# STM32L100RCT6 register map
File version: 1.0
Registers are 32-bit, access not given, reset 0x0 unless marked. A register's access mark holds for its fields unless they carry their own. Offsets are from the block's base; [hi:lo] are bit positions; {n}, {i} and the like mark numbered series; 'fields as' and 'values as' point back to an identical list.

## COMP
Base 0x40007C00
Same registers: COMP1 0x40007C00, COMP12_COMMON 0x40007C00, COMP2 0x40007C01
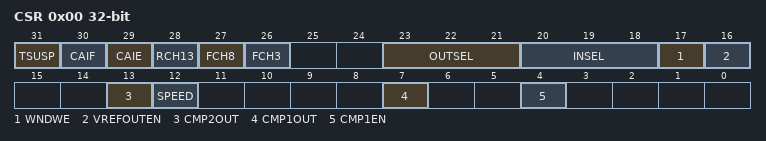
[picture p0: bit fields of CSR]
0x00 CSR
  [31] TSUSP, [30] CAIF, [29] CAIE, [28] RCH13, [27] FCH8, [26] FCH3, [23:21] OUTSEL, [20:18] INSEL, [17] WNDWE, [16] VREFOUTEN, [13] CMP2OUT, [12] SPEED, [7] CMP1OUT, [4] CMP1EN

## RI
Base 0x40007C04
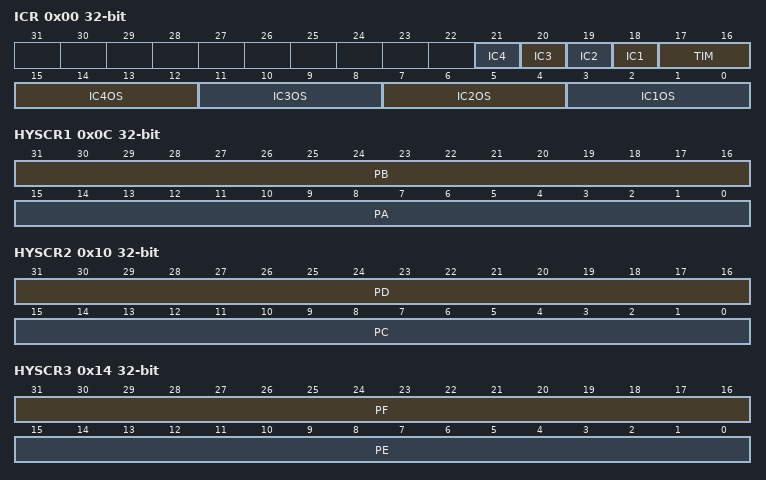
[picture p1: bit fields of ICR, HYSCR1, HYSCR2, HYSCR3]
0x00 ICR
  [n+17] IC{n} (n=1..4), [17:16] TIM, [4n-1:4n-4] IC{n}OS (n=1..4)
0x04 ASCR1
  [31] SCM, [26] VCOMP, [30:0] CH
0x08 ASCR2
  [16] CH0b, [28:4] GR6
0x0C HYSCR1
  [31:16] PB, [15:0] PA
0x10 HYSCR2
  [31:16] PD, [15:0] PC
0x14 HYSCR3
  [31:16] PF, [15:0] PE
0x18 HYSCR4
  [15:0] PG
0x1C ASMR1
  [15:0] PA
0x20 CMR1
  [15:0] PA
0x24 CICR1
  [15:0] PA
0x28 ASMR2
  [15:0] PB
0x2C CMR2
  [15:0] PB
0x30 CICR2
  [15:0] PB
0x34 ASMR3
  [15:0] PC
0x38 CMR3
  [15:0] PC
0x3C CICR3
  [15:0] PC
0x40 ASMR4
  [15:0] PF
0x44 CMR4
  [15:0] PF
0x48 CICR4
  [15:0] PF
0x4C ASMR5
  [15:0] PG
0x50 CMR5
  [15:0] PG
0x54 CICR5
  [15:0] PG

## SYSCFG
Base 0x40010000
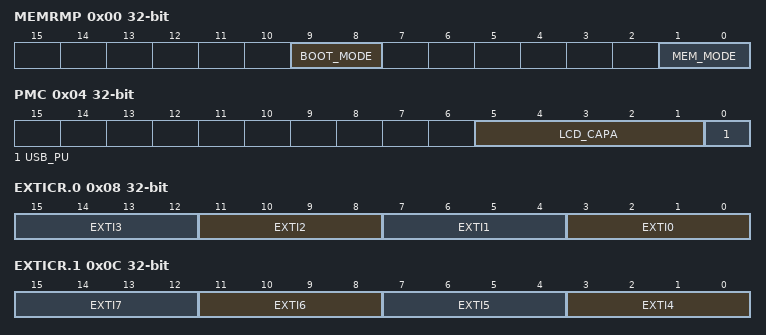
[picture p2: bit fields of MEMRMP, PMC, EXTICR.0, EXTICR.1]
0x00 MEMRMP
  [9:8] BOOT_MODE, [1:0] MEM_MODE
0x04 PMC
  [5:1] LCD_CAPA, [0] USB_PU
0x08 EXTICR.0
  [4n+3:4n] EXTI{n} (n=0..3)
0x0C EXTICR.1
  [4n-13:4n-16] EXTI{n} (n=4..7)
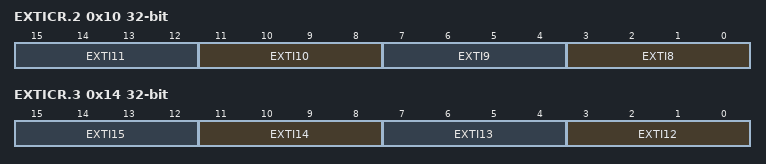
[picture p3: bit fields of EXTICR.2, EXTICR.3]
0x10 EXTICR.2
  [4n-29:4n-32] EXTI{n} (n=8..11)
0x14 EXTICR.3
  [4n-45:4n-48] EXTI{n} (n=12..15)

## EXTI
Base 0x40010400
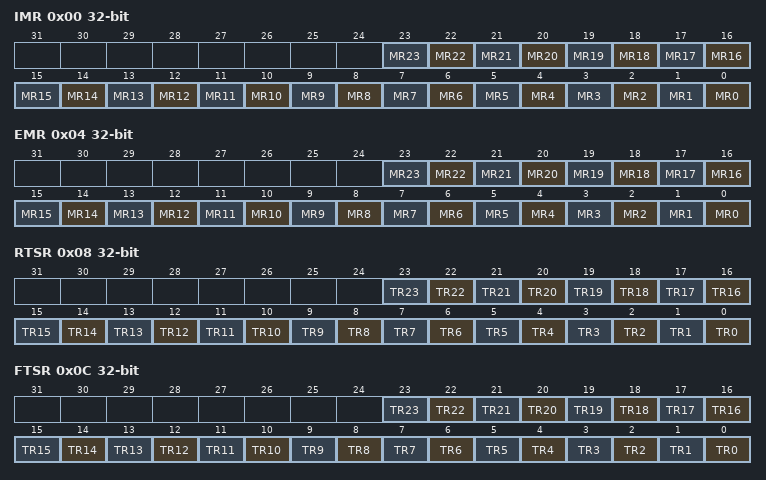
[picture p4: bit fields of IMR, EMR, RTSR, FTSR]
0x00 IMR
  [n] MR{n} (n=0..23)
0x04 EMR
  [n] MR{n} (n=0..23)
0x08 RTSR
  [n] TR{n} (n=0..23)
0x0C FTSR
  [n] TR{n} (n=0..23)
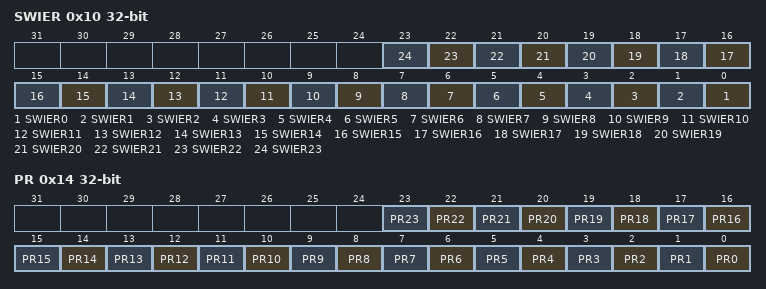
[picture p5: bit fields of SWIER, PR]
0x10 SWIER
  [n] SWIER{n} (n=0..23)
0x14 PR
  [n] PR{n} (n=0..23)

## ADC1
Base 0x40012400
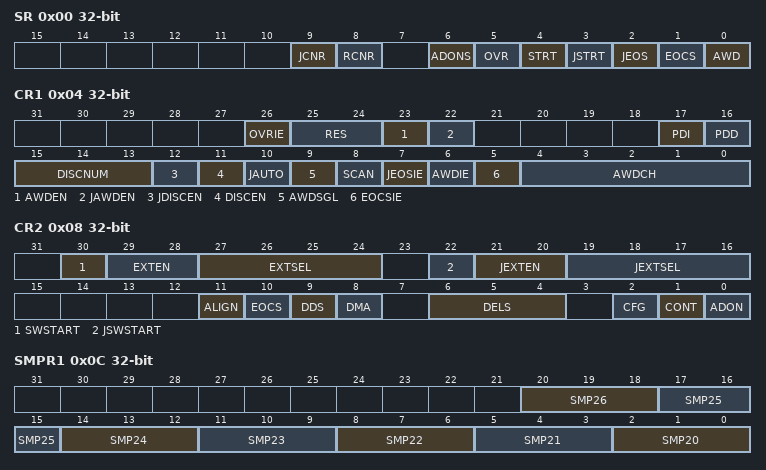
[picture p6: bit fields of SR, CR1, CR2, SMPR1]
0x00 SR
  [9] JCNR, [8] RCNR, [6] ADONS, [5] OVR, [4] STRT, [3] JSTRT, [2] JEOS, [1] EOCS, [0] AWD
0x04 CR1
  [26] OVRIE, [25:24] RES, [23] AWDEN, [22] JAWDEN, [17] PDI, [16] PDD, [15:13] DISCNUM, [12] JDISCEN, [11] DISCEN, [10] JAUTO, [9] AWDSGL, [8] SCAN, [7] JEOSIE, [6] AWDIE, [5] EOCSIE, [4:0] AWDCH
0x08 CR2
  [30] SWSTART, [29:28] EXTEN, [27:24] EXTSEL, [22] JSWSTART, [21:20] JEXTEN, [19:16] JEXTSEL, [11] ALIGN, [10] EOCS, [9] DDS, [8] DMA, [6:4] DELS, [2] CFG, [1] CONT, [0] ADON
0x0C SMPR1
  [3n-58:3n-60] SMP{n} (n=20..26)
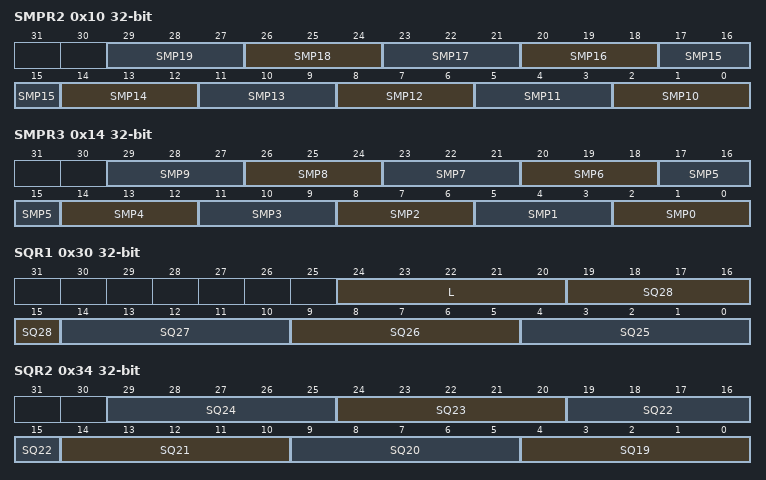
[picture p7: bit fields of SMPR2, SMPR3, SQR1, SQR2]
0x10 SMPR2
  [3n-28:3n-30] SMP{n} (n=10..19)
0x14 SMPR3
  [3n+2:3n] SMP{n} (n=0..9)
{0x14+4i} JOFR{i} (i=1..4)
  [11:0] JOFFSET{i}
0x28 HTR
  [11:0] HT
0x2C LTR
  [11:0] LT
0x30 SQR1
  [24:20] L, [5n-121:5n-125] SQ{n} (n=25..28)
0x34 SQR2
  [5n-91:5n-95] SQ{n} (n=19..24)
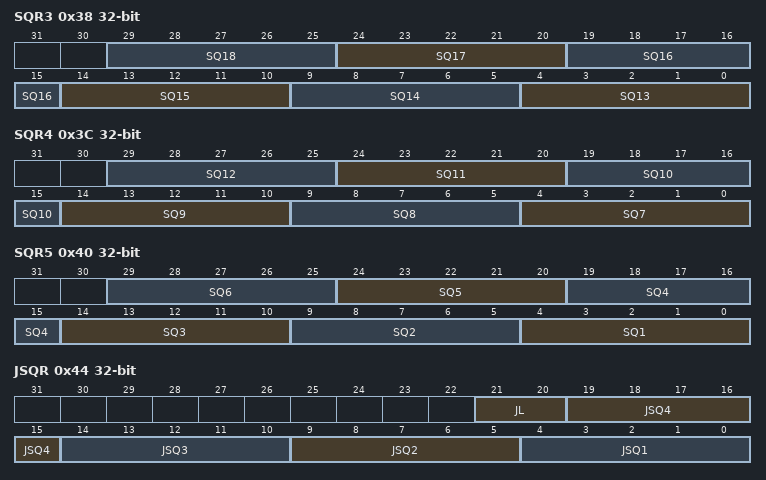
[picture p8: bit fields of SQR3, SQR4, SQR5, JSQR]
0x38 SQR3
  [5n-61:5n-65] SQ{n} (n=13..18)
0x3C SQR4
  [5n-31:5n-35] SQ{n} (n=7..12)
0x40 SQR5
  [5n-1:5n-5] SQ{n} (n=1..6)
0x44 JSQR
  [21:20] JL, [5n-1:5n-5] JSQ{n} (n=1..4)
{0x44+4i} JDR{i} (i=1..4)
  [15:0] JDATA
0x58 DR
  [15:0] DATA
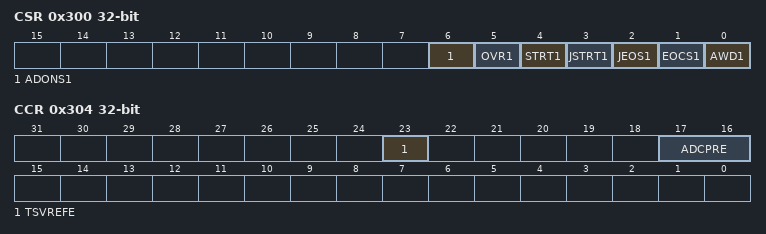
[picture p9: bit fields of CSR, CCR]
0x300 CSR
  [6] ADONS1, [5] OVR1, [4] STRT1, [3] JSTRT1, [2] JEOS1, [1] EOCS1, [0] AWD1
0x304 CCR
  [23] TSVREFE, [17:16] ADCPRE

## GPIOA
Base 0x40020000
Same registers: GPIOB 0x40020400, GPIOC 0x40020800, GPIOD 0x40020C00, GPIOH 0x40021400
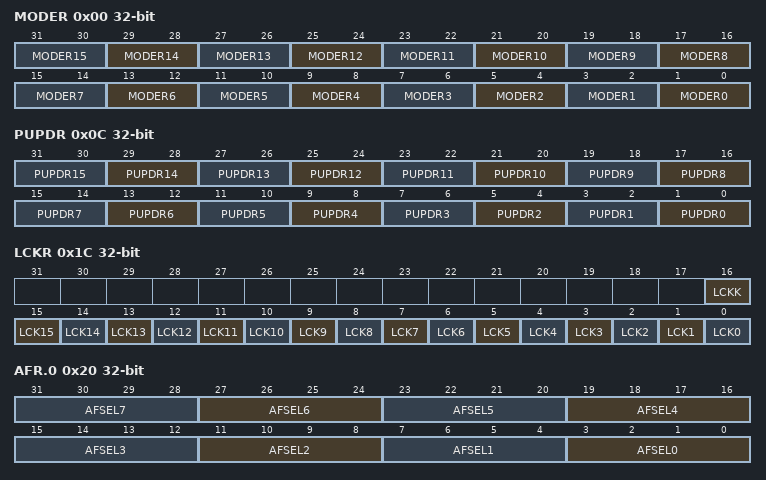
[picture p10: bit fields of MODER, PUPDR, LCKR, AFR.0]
0x00 MODER
  [2n+1:2n] MODER{n} (n=0..15)
0x04 OTYPER
0x08 OSPEEDR
0x0C PUPDR
  [2n+1:2n] PUPDR{n} (n=0..15)
0x10 IDR
0x14 ODR
0x18 BSRR
0x1C LCKR
  [16] LCKK, [n] LCK{n} (n=0..15)
0x20 AFR.0
  [4n+3:4n] AFSEL{n} (n=0..7)
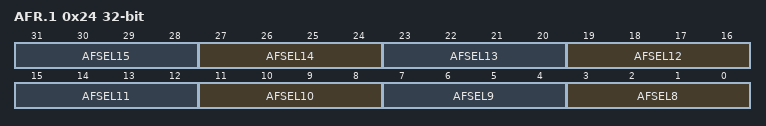
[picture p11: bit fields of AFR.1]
0x24 AFR.1
  [4n-29:4n-32] AFSEL{n} (n=8..15)

## CRC
Base 0x40023000
0x00 DR
0x04 IDR 8-bit
0x08 CR
  [0] RESET

## RCC
Base 0x40023800
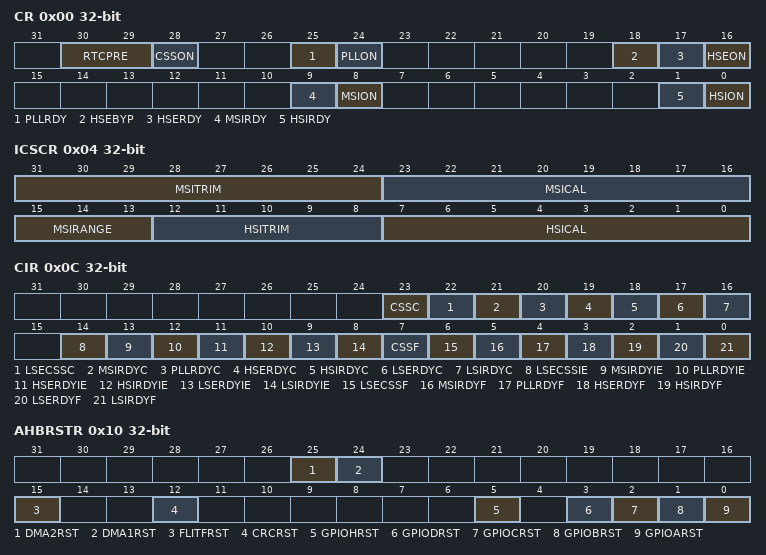
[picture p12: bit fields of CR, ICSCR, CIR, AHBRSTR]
0x00 CR
  [30:29] RTCPRE, [28] CSSON, [25] PLLRDY, [24] PLLON, [18] HSEBYP, [17] HSERDY, [16] HSEON, [9] MSIRDY, [8] MSION, [1] HSIRDY, [0] HSION
0x04 ICSCR
  [31:24] MSITRIM, [23:16] MSICAL, [15:13] MSIRANGE, [12:8] HSITRIM, [7:0] HSICAL
0x08 CFGR
  [30:28] MCOPRE, [26] MCOSEL_HSE, [26:25] MCOSEL_LSI, [24] MCOSEL_SYSCLK, [23] PLLDIV3, [23:22] PLLDIV4, [21:18] PLLMUL, [16] PLLSRC, [13:11] PPRE2, [10:8] PPRE1, [7:4] HPRE, [3:2] SWS, [1:0] SW
0x0C CIR
  [23] CSSC, [22] LSECSSC, [21] MSIRDYC, [20] PLLRDYC, [19] HSERDYC, [18] HSIRDYC, [17] LSERDYC, [16] LSIRDYC, [14] LSECSSIE, [13] MSIRDYIE, [12] PLLRDYIE, [11] HSERDYIE, [10] HSIRDYIE, [9] LSERDYIE, [8] LSIRDYIE, [7] CSSF, [6] LSECSSF, [5] MSIRDYF, [4] PLLRDYF, [3] HSERDYF, [2] HSIRDYF, [1] LSERDYF, [0] LSIRDYF
0x10 AHBRSTR
  [25] DMA2RST, [24] DMA1RST, [15] FLITFRST, [12] CRCRST, [5] GPIOHRST, [3] GPIODRST, [2] GPIOCRST, [1] GPIOBRST, [0] GPIOARST
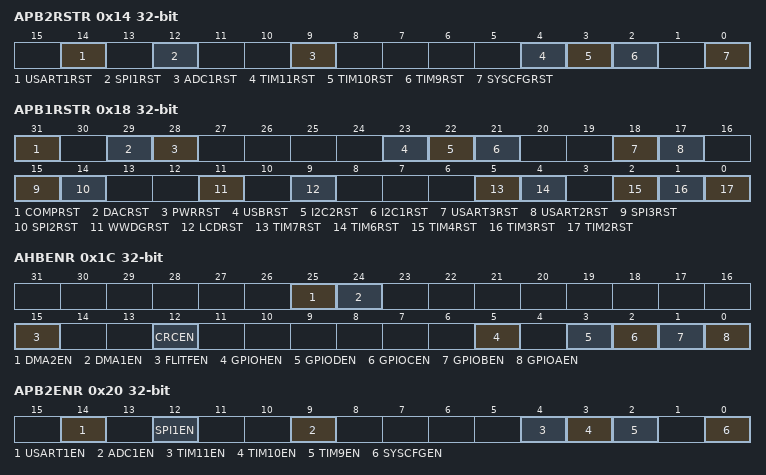
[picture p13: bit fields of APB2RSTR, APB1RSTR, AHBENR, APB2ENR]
0x14 APB2RSTR
  [14] USART1RST, [12] SPI1RST, [9] ADC1RST, [4] TIM11RST, [3] TIM10RST, [2] TIM9RST, [0] SYSCFGRST
0x18 APB1RSTR
  [31] COMPRST, [29] DACRST, [28] PWRRST, [23] USBRST, [22] I2C2RST, [21] I2C1RST, [18] USART3RST, [17] USART2RST, [15] SPI3RST, [14] SPI2RST, [11] WWDGRST, [9] LCDRST, [5] TIM7RST, [4] TIM6RST, [2] TIM4RST, [1] TIM3RST, [0] TIM2RST
0x1C AHBENR
  [25] DMA2EN, [24] DMA1EN, [15] FLITFEN, [12] CRCEN, [5] GPIOHEN, [3] GPIODEN, [2] GPIOCEN, [1] GPIOBEN, [0] GPIOAEN
0x20 APB2ENR
  [14] USART1EN, [12] SPI1EN, [9] ADC1EN, [4] TIM11EN, [3] TIM10EN, [2] TIM9EN, [0] SYSCFGEN
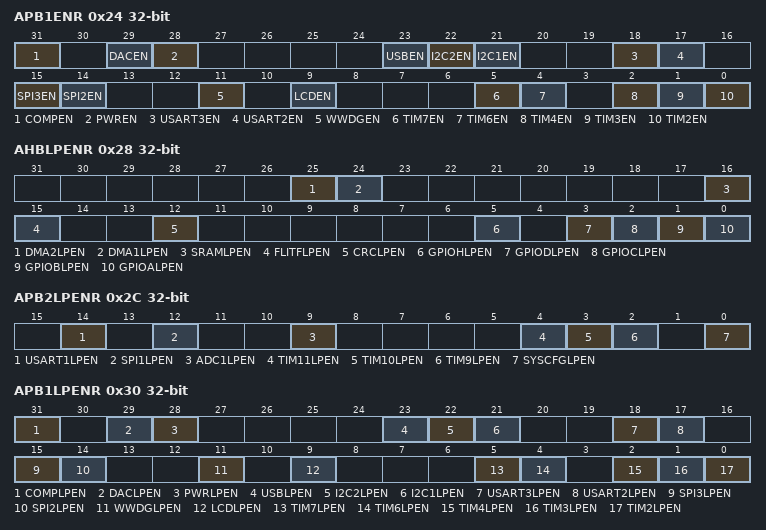
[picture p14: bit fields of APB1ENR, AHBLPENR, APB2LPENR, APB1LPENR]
0x24 APB1ENR
  [31] COMPEN, [29] DACEN, [28] PWREN, [23] USBEN, [22] I2C2EN, [21] I2C1EN, [18] USART3EN, [17] USART2EN, [15] SPI3EN, [14] SPI2EN, [11] WWDGEN, [9] LCDEN, [5] TIM7EN, [4] TIM6EN, [2] TIM4EN, [1] TIM3EN, [0] TIM2EN
0x28 AHBLPENR
  [25] DMA2LPEN, [24] DMA1LPEN, [16] SRAMLPEN, [15] FLITFLPEN, [12] CRCLPEN, [5] GPIOHLPEN, [3] GPIODLPEN, [2] GPIOCLPEN, [1] GPIOBLPEN, [0] GPIOALPEN
0x2C APB2LPENR
  [14] USART1LPEN, [12] SPI1LPEN, [9] ADC1LPEN, [4] TIM11LPEN, [3] TIM10LPEN, [2] TIM9LPEN, [0] SYSCFGLPEN
0x30 APB1LPENR
  [31] COMPLPEN, [29] DACLPEN, [28] PWRLPEN, [23] USBLPEN, [22] I2C2LPEN, [21] I2C1LPEN, [18] USART3LPEN, [17] USART2LPEN, [15] SPI3LPEN, [14] SPI2LPEN, [11] WWDGLPEN, [9] LCDLPEN, [5] TIM7LPEN, [4] TIM6LPEN, [2] TIM4LPEN, [1] TIM3LPEN, [0] TIM2LPEN
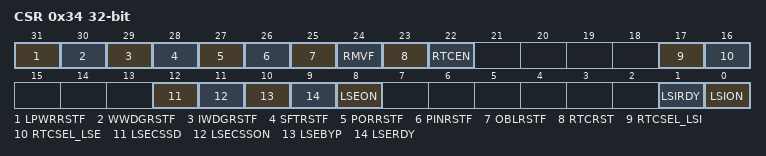
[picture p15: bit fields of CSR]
0x34 CSR
  [31] LPWRRSTF, [30] WWDGRSTF, [29] IWDGRSTF, [28] SFTRSTF, [27] PORRSTF, [26] PINRSTF, [25] OBLRSTF, [24] RMVF, [23] RTCRST, [22] RTCEN, [17] RTCSEL_LSI, [16] RTCSEL_LSE, [12] LSECSSD, [11] LSECSSON, [10] LSEBYP, [9] LSERDY, [8] LSEON, [1] LSIRDY, [0] LSION

## FLASH
Base 0x40023C00
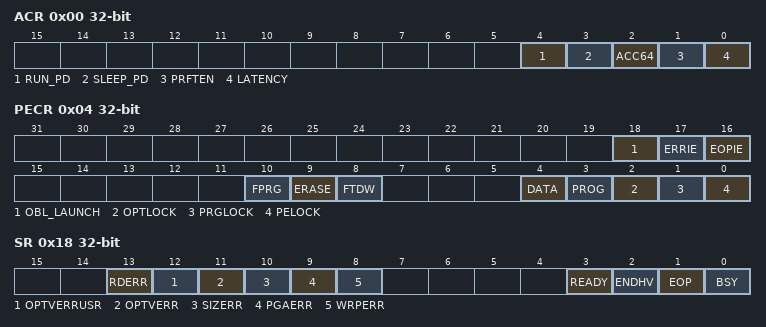
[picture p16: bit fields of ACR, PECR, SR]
0x00 ACR
  [4] RUN_PD, [3] SLEEP_PD, [2] ACC64, [1] PRFTEN, [0] LATENCY
0x04 PECR
  [18] OBL_LAUNCH, [17] ERRIE, [16] EOPIE, [10] FPRG, [9] ERASE, [8] FTDW, [4] DATA, [3] PROG, [2] OPTLOCK, [1] PRGLOCK, [0] PELOCK
0x08 PDKEYR
0x0C PEKEYR
0x10 PRGKEYR
0x14 OPTKEYR
0x18 SR
  [13] RDERR, [12] OPTVERRUSR, [11] OPTVERR, [10] SIZERR, [9] PGAERR, [8] WRPERR, [3] READY, [2] ENDHV, [1] EOP, [0] BSY
0x1C OBR
  [22] nRST_STDBY, [21] nRST_STOP, [22:20] USER, [19:16] BOR_LEV, [7:0] RDPRT
0x20 WRPR1
  [31:0] WRP
0x80 WRPR2
  [31:0] WRP

## DMA1
Base 0x40026000
Same registers: DMA2 0x40026400
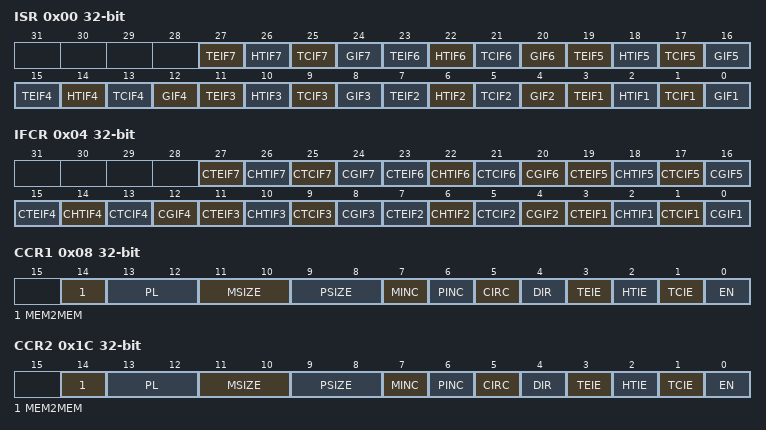
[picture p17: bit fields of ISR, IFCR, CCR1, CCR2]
0x00 ISR
  [4n-1] TEIF{n} (n=1..7), [4n-2] HTIF{n} (n=1..7), [4n-3] TCIF{n} (n=1..7), [4n-4] GIF{n} (n=1..7)
0x04 IFCR
  [4n-1] CTEIF{n} (n=1..7), [4n-2] CHTIF{n} (n=1..7), [4n-3] CTCIF{n} (n=1..7), [4n-4] CGIF{n} (n=1..7)
0x08 CCR1
  [14] MEM2MEM, [13:12] PL, [11:10] MSIZE, [9:8] PSIZE, [7] MINC, [6] PINC, [5] CIRC, [4] DIR, [3] TEIE, [2] HTIE, [1] TCIE, [0] EN
0x0C CNDTR1
  [15:0] NDT
0x10 CPAR1
  [31:0] PA
{0x0+0x14*i} CMAR{i} (i=1..7)
  [31:0] MA
0x1C CCR2
  fields as CCR1
0x20 CNDTR2
  [15:0] NDT
0x24 CPAR2
  [31:0] PA
0x30 CCR3
  fields as CCR1
0x34 CNDTR3
  [15:0] NDT
0x38 CPAR3
  [31:0] PA
0x44 CCR4
  fields as CCR1
0x48 CNDTR4
  [15:0] NDT
0x4C CPAR4
  [31:0] PA
0x58 CCR5
  fields as CCR1
0x5C CNDTR5
  [15:0] NDT
0x60 CPAR5
  [31:0] PA
0x6C CCR6
  fields as CCR1
0x70 CNDTR6
  [15:0] NDT
0x74 CPAR6
  [31:0] PA
0x80 CCR7
  fields as CCR1
0x84 CNDTR7
  [15:0] NDT
0x88 CPAR7
  [31:0] PA

## DBGMCU
Base 0xE0042000
0x00 IDCODE
  [31:16] REV_ID, [11:0] DEV_ID
0x04 CR
  [7:6] TRACE_MODE, [5] TRACE_IOEN, [2] DBG_STANDBY, [1] DBG_STOP, [0] DBG_SLEEP
0x08 APB1FZ
  [22] DBG_I2C2_SMBUS_TIMEOUT, [21] DBG_I2C1_SMBUS_TIMEOUT, [12] DBG_IWDG_STOP, [11] DBG_WWDG_STOP, [10] DBG_RTC_STOP, [5] DBG_TIM7_STOP, [4] DBG_TIM6_STOP, [2] DBG_TIM4_STOP, [1] DBG_TIM3_STOP, [0] DBG_TIM2_STOP
0x0C APB2FZ
  [4] DBG_TIM11_STOP, [3] DBG_TIM10_STOP, [2] DBG_TIM9_STOP
